# NUC1xx_registers register map
File version: 0.1
NUC1xx_registers Microcontroller dummy device
CPU: 
Registers are 32-bit, read-write, reset 0x0 unless marked. A register's access mark holds for its fields unless they carry their own. Offsets are from the block's base; lines under a group give offsets from that group; [hi:lo] are bit positions; {n}, {i} and the like mark numbered series; 'fields as' and 'values as' point back to an identical list; <NAME> marks a mode.

## Memory map
0x40004000 WDT size 0x4 — Registers group
0x40008000 RTC size 0x34 — Registers group
0x40010000 TMR0 size 0x10 — Registers group
0x40010020 TMR1 size 0x10 — Registers group
0x40020000 I2C0 size 0x34 — Registers group
0x40030000 SPI0 size 0xC — Registers group
0x40034000 SPI1 size 0xC — Registers group
0x40040000 PWMA size 0x48 — Registers group
0x40050000 UART0 size 0x34 — Registers group
0x40060000 USB size 0x1C — Registers group
0x400D0000 CMP size 0xC — Registers group
0x400E0000 ADC size 0x38 — Registers group
0x40100000 PS2 size 0x20 — Registers group
0x40110000 TMR2 size 0x10 — Registers group
0x40110020 TMR3 size 0x10 — Registers group
0x40120000 I2C1 size 0x34 — Registers group
0x40130000 SPI2 size 0xC — Registers group
0x40134000 SPI3 size 0xC — Registers group
0x40140000 PWMB size 0x48 — Registers group
0x40150000 UART1 size 0x34 — Registers group
0x40154000 UART2 size 0x34 — Registers group
0x40180000 CAN size 0x1C — Registers group
0x401A0000 I2S size 0x18 — Registers group
0x50000000 GCR size 0x10 — Registers group
0x50000200 CLK size 0x28 — Registers group
0x50000300 INT size 0x88 — Registers group
0x50004000 GPA size 0x24 — Registers group
0x50004040 GPB size 0x24 — Registers group
0x50004080 GPC size 0x24 — Registers group
0x500040C0 GPD size 0x24 — Registers group
0x50004100 GPE size 0x24 — Registers group
0x50004180 GPIO size 0x4 — Registers group
0x50004200 GPA_BITS size 0x40 — Registers group
0x50004240 GPB_BITS size 0x40 — Registers group
0x50004280 GPC_BITS size 0x40 — Registers group
0x500042C0 GPD_BITS size 0x40 — Registers group
0x50004300 GPE_BITS size 0x40 — Registers group
{0x50008000+0x100*n} PDMA{n} size 0x28 (n=0..8) — Registers group
0x50008F00 PDMA_GCR size 0x14 — Registers group
0x5000C000 FMC size 0x1C — Registers group
0x50010000 EBI size 0x8 — Registers group
0xE000E000 SCS blocks up to offset 0x1C — Registers group

## CMP — Registers group
Base 0x400D0000
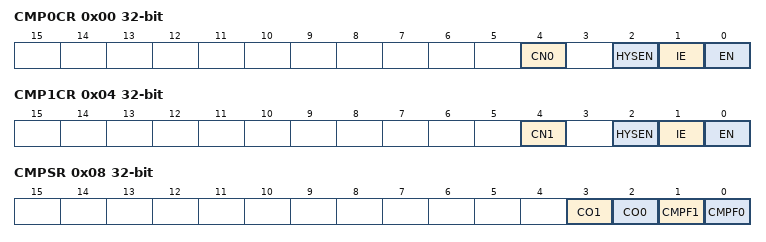
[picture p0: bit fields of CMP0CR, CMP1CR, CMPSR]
0x00 CMP0CR — Comparator0 Control Register
  [4] CN0 — Comparator0 negative input select 1 = The internal comparator reference voltage (Vref=1.2V) is selected as the negative comparator input 0 = The comparator0 reference pin CPN0 is selected as the negative comparator input
  [2] HYSEN — CMP0 Hysterisis Enable 1 = Enable comparator0 Hysterisis function; the typical range is 20mV. 0 = Disable comparator0 Hysterisis function (Default).
  [1] IE — Comparator0 Interrupt Enable 1 = Enable comparator0 interrupt function 0 = Disable comparator0 interrupt function Interrupt is generated if CMP0IE bit is set to 1 after comparator0 conversion finished.
  [0] EN — Comparator0 Enable 1 = Enable 0 = Disable Comparator0 output needs wait 10 us stable time after CMP0EN is set
0x04 CMP1CR — Comparator1 Control Register
  [4] CN1 — Comparator1 negative input select 1 = The internal comparator reference voltage (Vref=1.2V) is selected as the negative comparator input 0 = The comparator1 reference pin CPN1 is selected as the negative comparator input
  [2] HYSEN — Comparator1 Hysterisis Enable 1 = Enable comparator1 Hysterisis function; the typical range is 20mV. 0 = Disable comparator1 Hysterisis function (Default).
  [1] IE — Comparator1 Interrupt Enable 1 = Enable Comparator1 interrupt function 0 = Disable Comparator1 interrupt function Interrupt is generated if CMP1IE bit is set to 1 after comparator1 conversion finished.
  [0] EN — Comparator1 Enable 1 = Enable 0 = Disable Comparator1 output needs wait 10 us stable time after CMP1EN is set
0x08 CMPSR — Comparator Channel Selection Enable Register
  [3] CO1 ro — Comparator1 Output Synchronized to the APB clock to allow reading by software. Cleared when the comparator is disabled (CMP1EN = 0).
  [2] CO0 ro — Comparator0 Output Synchronized to the APB clock to allow reading by software. Cleared when the comparator is disabled (CMP0EN = 0).
  [1] CMPF1 write-1-clears — Comparator1 Flag This bit is set by hardware whenever the comparator1 output changes state. This will cause an interrupt if CMP1IE set. Write 1 to clear this bit to zero.
  [0] CMPF0 write-1-clears — Comparator0 Flag This bit is set by hardware whenever the comparator0 output changes state. This will cause an interrupt if CMP0IE set. Write 1 to clear this bit to zero.
